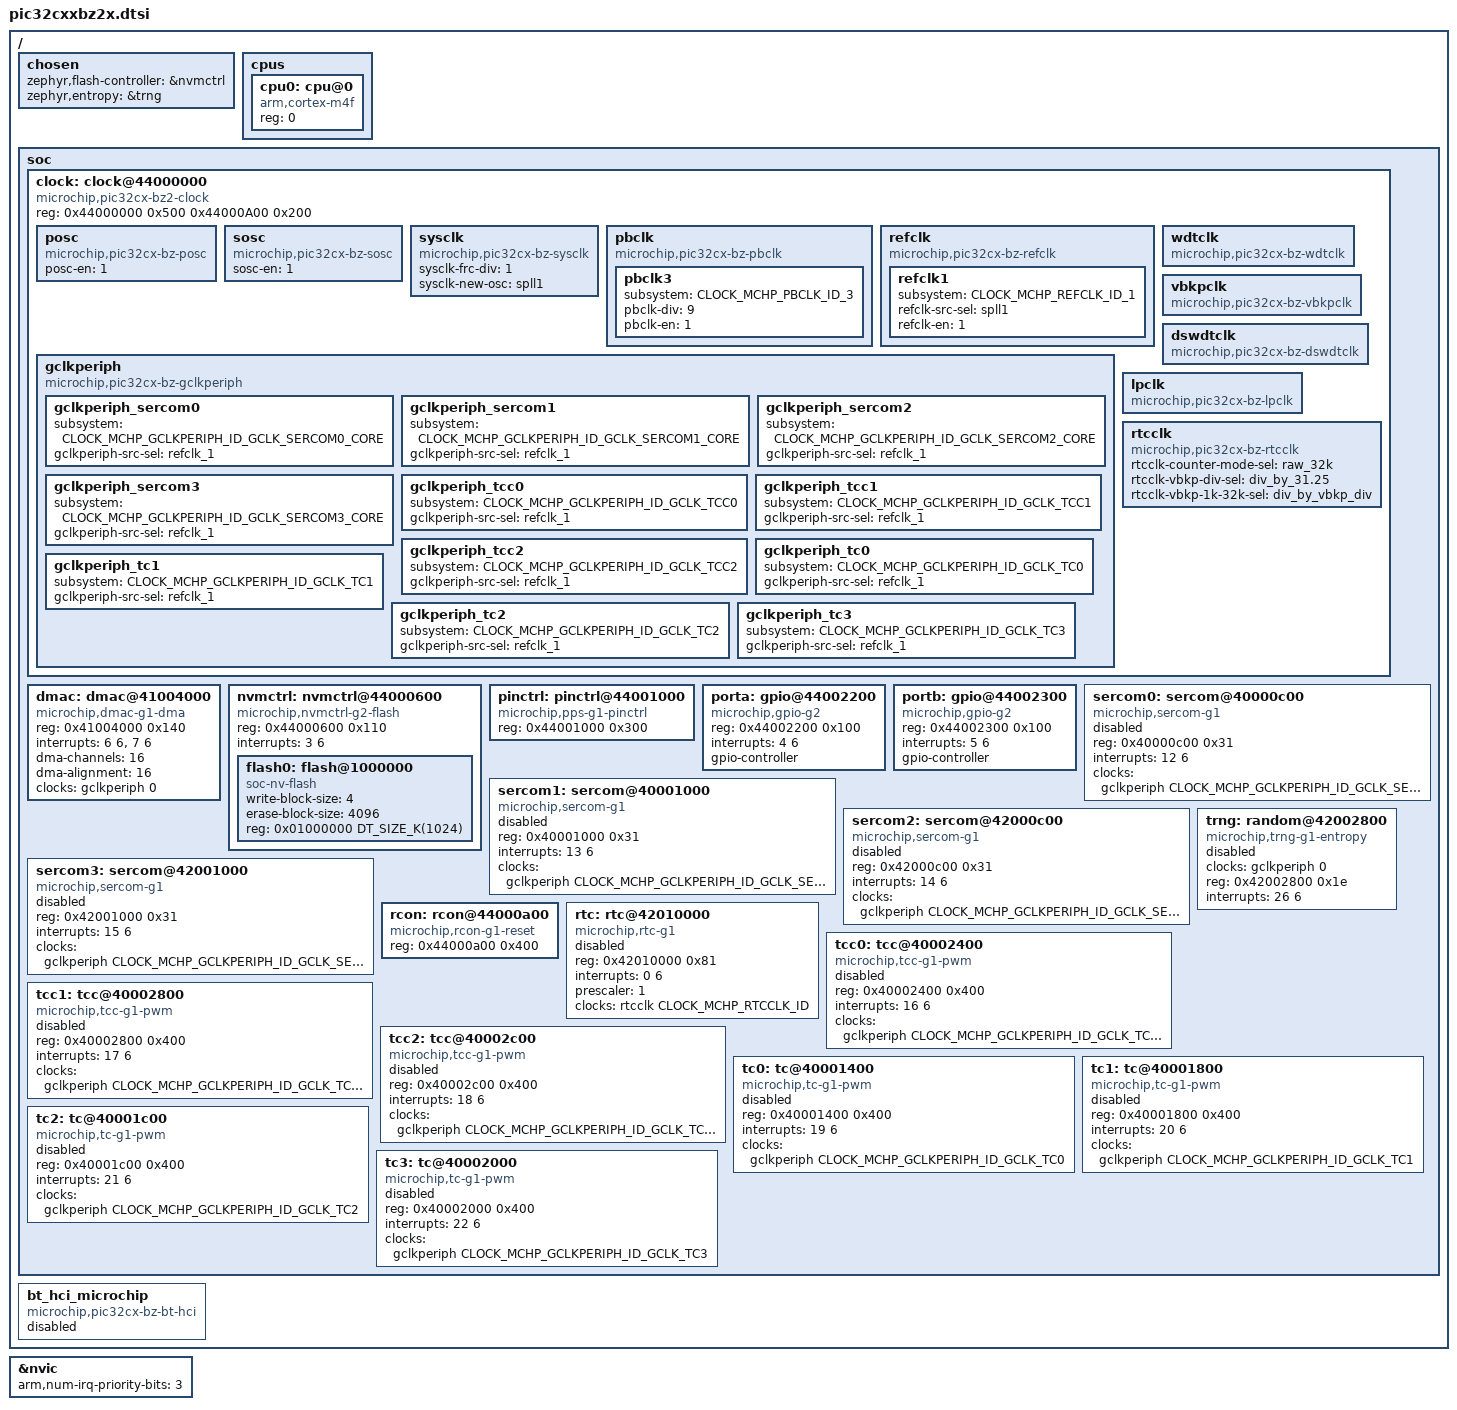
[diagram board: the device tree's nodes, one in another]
/*
 * Copyright (c) 2025 Microchip Technology Inc.
 *
 * SPDX-License-Identifier: Apache-2.0
 */

#include <arm/armv7-m.dtsi>
#include <zephyr/dt-bindings/gpio/gpio.h>
#include <zephyr/dt-bindings/pwm/pwm.h>
#include <zephyr/dt-bindings/clock/mchp_pic32cx_bz2_clock.h>

/ {
	chosen {
		zephyr,flash-controller = &nvmctrl;
		zephyr,entropy = &trng;
	};

	cpus {
		#address-cells = <1>;
		#size-cells = <0>;

		cpu0: cpu@0 {
			device_type = "cpu";
			compatible = "arm,cortex-m4f";
			reg = <0>;
			#address-cells = <1>;
			#size-cells = <1>;
		};
	};

	soc {
		clock: clock@44000000 {
			compatible = "microchip,pic32cx-bz2-clock";
			reg =	<
			0x44000000 0x500
			0x44000A00 0x200>;// cfg, cru
			posc: posc {
				compatible = "microchip,pic32cx-bz-posc";
				posc-en = <1>;
			};
			sosc: sosc {
				compatible = "microchip,pic32cx-bz-sosc";
				sosc-en = <1>;
			};
			sysclk: sysclk {
				compatible = "microchip,pic32cx-bz-sysclk";
				sysclk-frc-div = <1>;
				sysclk-new-osc = "spll1";
			};
			pbclk: pbclk {
				compatible = "microchip,pic32cx-bz-pbclk";
				pbclk3 {
					subsystem = <CLOCK_MCHP_PBCLK_ID_3>;
					pbclk-div = <9>;
					pbclk-en = <1>;
				};
			};
			refclk: refclk {
				compatible = "microchip,pic32cx-bz-refclk";
				refclk1 {
					subsystem = <CLOCK_MCHP_REFCLK_ID_1>;
					refclk-src-sel = "spll1";
					refclk-en = <1>;
				};
			};
			gclkperiph: gclkperiph {
				compatible = "microchip,pic32cx-bz-gclkperiph";
				#clock-cells = <1>;
				gclkperiph_sercom0 {
					subsystem = <CLOCK_MCHP_GCLKPERIPH_ID_GCLK_SERCOM0_CORE>;
					gclkperiph-src-sel = "refclk_1";
				};
				gclkperiph_sercom1 {
					subsystem = <CLOCK_MCHP_GCLKPERIPH_ID_GCLK_SERCOM1_CORE>;
					gclkperiph-src-sel = "refclk_1";
				};
				gclkperiph_sercom2 {
					subsystem = <CLOCK_MCHP_GCLKPERIPH_ID_GCLK_SERCOM2_CORE>;
					gclkperiph-src-sel = "refclk_1";
				};
				gclkperiph_sercom3 {
					subsystem = <CLOCK_MCHP_GCLKPERIPH_ID_GCLK_SERCOM3_CORE>;
					gclkperiph-src-sel = "refclk_1";
				};
				gclkperiph_tcc0 {
					subsystem = <CLOCK_MCHP_GCLKPERIPH_ID_GCLK_TCC0>;
					gclkperiph-src-sel = "refclk_1";
				};
				gclkperiph_tcc1 {
					subsystem = <CLOCK_MCHP_GCLKPERIPH_ID_GCLK_TCC1>;
					gclkperiph-src-sel = "refclk_1";
				};
				gclkperiph_tcc2 {
					subsystem = <CLOCK_MCHP_GCLKPERIPH_ID_GCLK_TCC2>;
					gclkperiph-src-sel = "refclk_1";
				};
				gclkperiph_tc0 {
					subsystem = <CLOCK_MCHP_GCLKPERIPH_ID_GCLK_TC0>;
					gclkperiph-src-sel = "refclk_1";
				};
				gclkperiph_tc1 {
					subsystem = <CLOCK_MCHP_GCLKPERIPH_ID_GCLK_TC1>;
					gclkperiph-src-sel = "refclk_1";
				};
				gclkperiph_tc2 {
					subsystem = <CLOCK_MCHP_GCLKPERIPH_ID_GCLK_TC2>;
					gclkperiph-src-sel = "refclk_1";
				};
				gclkperiph_tc3 {
					subsystem = <CLOCK_MCHP_GCLKPERIPH_ID_GCLK_TC3>;
					gclkperiph-src-sel = "refclk_1";
				};
			};
			wdtclk: wdtclk {
				compatible = "microchip,pic32cx-bz-wdtclk";
			};
			vbkpclk: vbkpclk {
				compatible = "microchip,pic32cx-bz-vbkpclk";
			};
			dswdtclk: dswdtclk {
				compatible = "microchip,pic32cx-bz-dswdtclk";
			};
			lpclk: lpclk {
				compatible = "microchip,pic32cx-bz-lpclk";
			};
			rtcclk: rtcclk {
				compatible = "microchip,pic32cx-bz-rtcclk";
				#clock-cells = <1>;
				rtcclk-counter-mode-sel = "raw_32k";
				rtcclk-vbkp-div-sel = "div_by_31.25";
				rtcclk-vbkp-1k-32k-sel = "div_by_vbkp_div";
			};
		};
		dmac: dmac@41004000 {
			compatible = "microchip,dmac-g1-dma";
			reg = <0x41004000 0x140>;
			interrupts = <6 6>, <7 6>;
			dma-channels = <16>;
			dma-alignment = <16>;
			#dma-cells = <2>;
			clocks = <&gclkperiph 0>;
			clock-names = "gclk";
		};

		nvmctrl: nvmctrl@44000600  {
			compatible = "microchip,nvmctrl-g2-flash";
			reg = <0x44000600 0x110>;
			interrupts = <3 6>;
			#address-cells = <1>;
			#size-cells = <1>;

			flash0: flash@1000000 {
				compatible = "soc-nv-flash";
				write-block-size = <4>;
				erase-block-size = <4096>;
				reg = <0x01000000 DT_SIZE_K(1024)>;
			};
		};

		pinctrl: pinctrl@44001000 {
			compatible = "microchip,pps-g1-pinctrl";
			reg = <0x44001000 0x300>;
			#address-cells = <1>;
			status = "okay";
		};

		porta: gpio@44002200 {
			compatible = "microchip,gpio-g2";
			reg = <0x44002200 0x100>;
			interrupts = <4 6>;
			gpio-controller;
			#gpio-cells = <2>;
		};

		portb: gpio@44002300 {
			compatible = "microchip,gpio-g2";
			reg = <0x44002300 0x100>;
			interrupts = <5 6>;
			gpio-controller;
			#gpio-cells = <2>;
		};

		sercom0: sercom@40000c00 {
			compatible = "microchip,sercom-g1";
			reg = <0x40000c00 0x31>;
			interrupts = <12 6>;
			clocks = <&gclkperiph CLOCK_MCHP_GCLKPERIPH_ID_GCLK_SERCOM0_CORE>;
			clock-names = "gclk";
			status = "disabled";
		};

		sercom1: sercom@40001000 {
			compatible = "microchip,sercom-g1";
			reg = <0x40001000 0x31>;
			interrupts = <13 6>;
			clocks = <&gclkperiph CLOCK_MCHP_GCLKPERIPH_ID_GCLK_SERCOM1_CORE>;
			clock-names = "gclk";
			status = "disabled";
		};

		sercom2: sercom@42000c00 {
			compatible = "microchip,sercom-g1";
			reg = <0x42000c00 0x31>;
			interrupts = <14 6>;
			clocks = <&gclkperiph CLOCK_MCHP_GCLKPERIPH_ID_GCLK_SERCOM2_CORE>;
			clock-names = "gclk";
			status = "disabled";
		};

		sercom3: sercom@42001000 {
			compatible = "microchip,sercom-g1";
			reg = <0x42001000 0x31>;
			interrupts = <15 6>;
			clocks = <&gclkperiph CLOCK_MCHP_GCLKPERIPH_ID_GCLK_SERCOM3_CORE>;
			clock-names = "gclk";
			status = "disabled";
		};

		trng: random@42002800 {
			compatible = "microchip,trng-g1-entropy";
			status = "disabled";
			clocks = <&gclkperiph 0>;
			clock-names = "gclk";
			reg = <0x42002800 0x1e>;
			interrupts = <26 6>;
		};

		rcon: rcon@44000a00 {
			compatible = "microchip,rcon-g1-reset";
			status = "okay";
			reg = <0x44000a00 0x400>;
		};

		rtc: rtc@42010000 {
			compatible = "microchip,rtc-g1";
			status = "disabled";
			reg = <0x42010000 0x81>;
			interrupts = <0 6>;
			prescaler = <1>;
			clocks = <&rtcclk CLOCK_MCHP_RTCCLK_ID>;
			clock-names = "rtcclk";
		};

		tcc0: tcc@40002400 {
			compatible = "microchip,tcc-g1-pwm";
			status = "disabled";
			reg = <0x40002400 0x400>;
			interrupts = <16 6>;
			clocks = <&gclkperiph CLOCK_MCHP_GCLKPERIPH_ID_GCLK_TCC0>;
			clock-names = "gclk";
		};

		tcc1: tcc@40002800 {
			compatible = "microchip,tcc-g1-pwm";
			status = "disabled";
			reg = <0x40002800 0x400>;
			interrupts = <17 6>;
			clocks = <&gclkperiph CLOCK_MCHP_GCLKPERIPH_ID_GCLK_TCC1>;
			clock-names = "gclk";
		};

		tcc2: tcc@40002c00 {
			compatible = "microchip,tcc-g1-pwm";
			status = "disabled";
			reg = <0x40002c00 0x400>;
			interrupts = <18 6>;
			clocks = <&gclkperiph CLOCK_MCHP_GCLKPERIPH_ID_GCLK_TCC2>;
			clock-names = "gclk";
		};

		tc0: tc@40001400 {
			compatible = "microchip,tc-g1-pwm";
			status = "disabled";
			reg = <0x40001400 0x400>;
			interrupts = <19 6>;
			clocks = <&gclkperiph CLOCK_MCHP_GCLKPERIPH_ID_GCLK_TC0>;
			clock-names = "gclk";
		};

		tc1: tc@40001800 {
			compatible = "microchip,tc-g1-pwm";
			status = "disabled";
			reg = <0x40001800 0x400>;
			interrupts = <20 6>;
			clocks = <&gclkperiph CLOCK_MCHP_GCLKPERIPH_ID_GCLK_TC1>;
			clock-names = "gclk";
		};

		tc2: tc@40001c00 {
			compatible = "microchip,tc-g1-pwm";
			status = "disabled";
			reg = <0x40001c00 0x400>;
			interrupts = <21 6>;
			clocks = <&gclkperiph CLOCK_MCHP_GCLKPERIPH_ID_GCLK_TC2>;
			clock-names = "gclk";
		};

		tc3: tc@40002000 {
			compatible = "microchip,tc-g1-pwm";
			status = "disabled";
			reg = <0x40002000 0x400>;
			interrupts = <22 6>;
			clocks = <&gclkperiph CLOCK_MCHP_GCLKPERIPH_ID_GCLK_TC3>;
			clock-names = "gclk";
		};
	};
	bt_hci_microchip: bt_hci_microchip {
		compatible = "microchip,pic32cx-bz-bt-hci";
		status = "disabled";
	};
};

&nvic {
	arm,num-irq-priority-bits = <3>;
};
